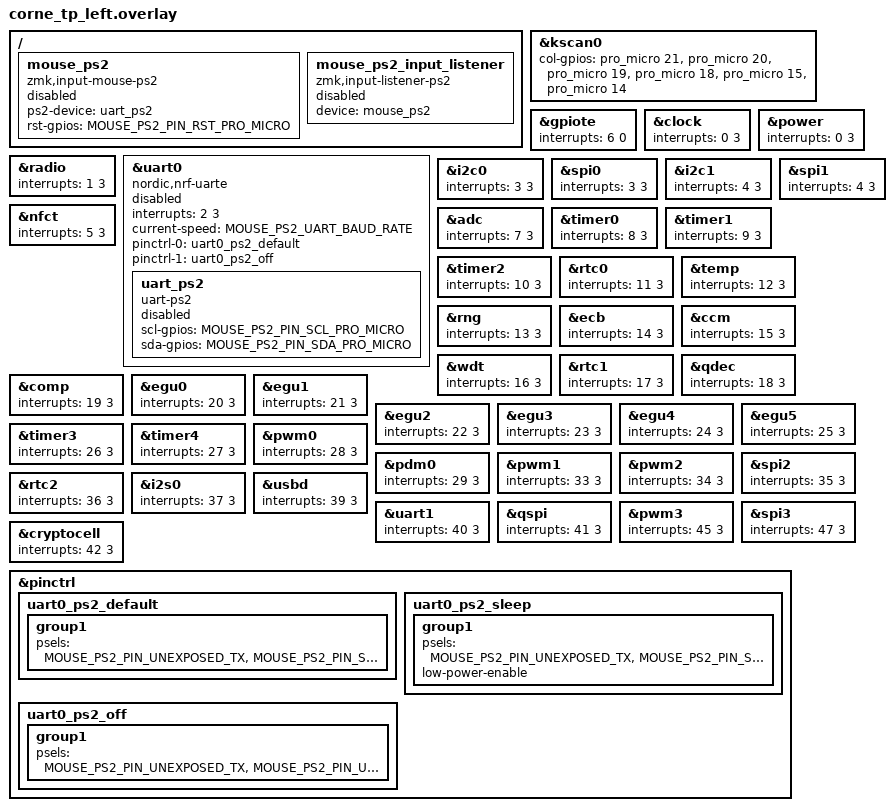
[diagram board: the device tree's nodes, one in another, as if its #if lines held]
/*
 * Copyright (c) 2020 Pete Johanson
 *
 * SPDX-License-Identifier: MIT
 */

#include "corne_tp.dtsi"

&kscan0 {
    col-gpios
        = <&pro_micro 21 GPIO_ACTIVE_HIGH>
        , <&pro_micro 20 GPIO_ACTIVE_HIGH>
        , <&pro_micro 19 GPIO_ACTIVE_HIGH>
        , <&pro_micro 18 GPIO_ACTIVE_HIGH>
        , <&pro_micro 15 GPIO_ACTIVE_HIGH>
        , <&pro_micro 14 GPIO_ACTIVE_HIGH>
        ;
};

#ifdef TRACKPOINT_ON_LEFT

#define MOUSE_PS2_DRIVER_UART

// The ideal pins are...
//   - D1 and D0 for clock and data, because they are high frequency.
//   - D8, D9, D16 or D10 for the trackpoint reset pin, because it doesn't
//     need to be high frequency (only needed if you are not using a reset
//     circuit)
//
// But on the corne keyboard, these pins are used for the backlight. So, this
// example config uses the pins D16 and D10 for clock and data and
// D9 for the reset circuit.
#define MOUSE_PS2_PIN_SCL_PRO_MICRO <&pro_micro 16 GPIO_ACTIVE_HIGH>
#define MOUSE_PS2_PIN_SDA_PRO_MICRO <&pro_micro 10 GPIO_ACTIVE_HIGH>

#define MOUSE_PS2_PIN_RST_PRO_MICRO <&pro_micro 9 GPIO_ACTIVE_HIGH>

// Configure SDA pin using the pinctrl notation
//
// Now configure SDA pin using the pinctrl notation. Make sure to use the same
// pin as in the pro micro notation, but convert it to the pinctrl notation.
//
// For the nice!nano you can find it on their pinout schematic, next to the
// pins, in the blue or violet boxes, with a format like `PX.YY` (P0.09).
//
// Enter it like `X, Y` without leading zeroes.
//
// Examples:
//      D1  - P0.06: 0, 6
// 		D0  - P0.08: 0, 8
//		D15 - P1.13: 1, 13
//		D16 - P0.10: 0, 10
//		D10 - P0.09: 0, 9
//
// We don't define the SCL pin, because UART uses a baud rate instead of
// a clock pin.
#define MOUSE_PS2_PIN_SDA_PINCTRL <NRF_PSEL(UART_RX, 0, 9)>

#define MOUSE_PS2_UART_BAUD_RATE <14400>

/*
 * PS/2 Mouse / Trackpoint - User Configuration if NOT using nice!nano
 *
 * WARNING: Do NOT change this if you are using a nice!nano v2 or clone.
 */

// Unexposed UART pins
// In UART two different pins are used for receiving and transmitting, but PS/2
// uses the same pin for both.
//
// The UART config still requires both pins to be configured. So we use one of
// the nrf52 pins that are not exposed on the nice!nano board.
//
// Do NOT change these if you are using a nice!nano (or a clone of it)
#define MOUSE_PS2_PIN_UNEXPOSED_TX <NRF_PSEL(UART_TX, 0, 27)>
#define MOUSE_PS2_PIN_UNEXPOSED_RX <NRF_PSEL(UART_RX, 0, 28)>


// Adjust GPIO interrupt priority to the highest level.
//
// IMPORTANT TLDR:
// If you are using the nice_nano_v2 board, you don't need to make changes to
// the config below and can leave it as it is.
//
// Explanation of these settings:
//
// PS/2 events must be processed within 30-50us, but frequently bluetooth and
// other interrupts take longer to finish.
//
// Therefore we change the default GPIO priority to the highest level (0) and
// demote all BT interrupt priorities by one level using the kconfig settings:
// - CONFIG_BT_CTLR_LLL_PRIO 1
// - CONFIG_BT_CTLR_ULL_HIGH_PRIO 2
// - CONFIG_BT_CTLR_ULL_LOW_PRIOCONFIG 2
//
// These config options are enabled automatically by the PS2 UART and GPIO
// drivers... so you don't have to enable them manually.
//
// Then we lower the interrupt priority of all other devices by 2 levels using
// the devicetree config below.
//
// This allows the PS/2 interrupts to be triggered faster and reduces
// transmission errors.
//
// If you are using the nice_nano_v2 board, you can reuse my config below.
//
// Otherwise, you can generate the interrupt overrides using this script:
// https://github.com/infused-kim/kb_zmk_ps2_mouse_trackpoint_driver/blob/main/scripts/gen_interrupt_priority_overrides.py
//
// Make sure to do it on a zephyr.dts where the interrupts have not been
// adjusted yet (i.e. a config that doesn't have the the following options
// enabled).
//
// If you are building using a toolchain you can find the zephyr.dts in the
// build directory, which by default is: `app/build/zephyr/zephyr.dts`
//
// If you are building using the github actions, copy the output of the build
// step `xxxx_right - nice_nano_v2 Devicetree file` into a file and run the
// script on it.

// gpiote should have the highest interrupt priority (0)
&gpiote {
    interrupts = < 6 0 >;
};

// All other priorities should be two levels lower than their defaults
// (which is usually 1 and should be demoted to 3)
&clock {
    interrupts = < 0 3 >;
};

&power {
    interrupts = < 0 3 >;
};

&radio {
    interrupts = < 1 3 >;
};

&uart0 {
    interrupts = < 2 3 >;
};

&i2c0 {
    interrupts = < 3 3 >;
};

&spi0 {
    interrupts = < 3 3 >;
};

&i2c1 {
    interrupts = < 4 3 >;
};

&spi1 {
    interrupts = < 4 3 >;
};

&nfct {
    interrupts = < 5 3 >;
};

&adc {
    interrupts = < 7 3 >;
};

&timer0 {
    interrupts = < 8 3 >;
};

&timer1 {
    interrupts = < 9 3 >;
};

&timer2 {
    interrupts = < 10 3 >;
};

&rtc0 {
    interrupts = < 11 3 >;
};

&temp {
    interrupts = < 12 3 >;
};

&rng {
    interrupts = < 13 3 >;
};

&ecb {
    interrupts = < 14 3 >;
};

&ccm {
    interrupts = < 15 3 >;
};

&wdt {
    interrupts = < 16 3 >;
};

&rtc1 {
    interrupts = < 17 3 >;
};

&qdec {
    interrupts = < 18 3 >;
};

&comp {
    interrupts = < 19 3 >;
};

&egu0 {
    interrupts = < 20 3 >;
};

&egu1 {
    interrupts = < 21 3 >;
};

&egu2 {
    interrupts = < 22 3 >;
};

&egu3 {
    interrupts = < 23 3 >;
};

&egu4 {
    interrupts = < 24 3 >;
};

&egu5 {
    interrupts = < 25 3 >;
};

&timer3 {
    interrupts = < 26 3 >;
};

&timer4 {
    interrupts = < 27 3 >;
};

&pwm0 {
    interrupts = < 28 3 >;
};

&pdm0 {
    interrupts = < 29 3 >;
};

&pwm1 {
    interrupts = < 33 3 >;
};

&pwm2 {
    interrupts = < 34 3 >;
};

&spi2 {
    interrupts = < 35 3 >;
};

&rtc2 {
    interrupts = < 36 3 >;
};

&i2s0 {
    interrupts = < 37 3 >;
};

&usbd {
    interrupts = < 39 3 >;
};

&uart1 {
    interrupts = < 40 3 >;
};

&qspi {
    interrupts = < 41 3 >;
};

&pwm3 {
    interrupts = < 45 3 >;
};

&spi3 {
    interrupts = < 47 3 >;
};

&cryptocell {
    interrupts = < 42 3 >;
};


/*
 * PS/2 Mouse / Trackpoint - Device Definitions
 *
 * WARNING: Do not change anything beyond here unless you know what you are
 *          doing.
 */


// Firmware with alternative pins
//
// This can safely be removed. It's only used in the example zmk-config repo
// to create an additional firmware with alternative PIN assignments.
//
// You can leave it or remove in your own zmk config. If you remove it, you
// should also remove the entry in `zmk-config-example/build.yaml` that uses
// it.
#ifdef MOUSE_PS2_ALT_PINS
    #undef MOUSE_PS2_PIN_SCL_PRO_MICRO
    #undef MOUSE_PS2_PIN_SDA_PRO_MICRO
    #undef MOUSE_PS2_PIN_SDA_PINCTRL

    #define MOUSE_PS2_PIN_SCL_PRO_MICRO <&pro_micro 1 GPIO_ACTIVE_HIGH>
    #define MOUSE_PS2_PIN_SDA_PRO_MICRO <&pro_micro 0 GPIO_ACTIVE_HIGH>
    #define MOUSE_PS2_PIN_SDA_PINCTRL <NRF_PSEL(UART_RX, 0, 8)>
#endif

// This define can be used in the keymap file to check whether the device tree
// configs in this file are present to void build errors on the side that does
// not have the mouse or TP
#define MOUSE_PS2_DT_PRESENT

&pinctrl {
	// This pinctrl state is used for receiving
	// For `UART_TX`, set an unused and unexposed pin
	// For `UART_RX`, set the PS/2 SDA pin number
	uart0_ps2_default: uart0_ps2_default {
		group1 {
			psels = MOUSE_PS2_PIN_UNEXPOSED_TX,
					MOUSE_PS2_PIN_SDA_PINCTRL;
		};
	};

	// Set this to the same pins as uart0_ps2_default
	uart0_ps2_sleep: uart0_ps2_sleep {
		group1 {
			psels = MOUSE_PS2_PIN_UNEXPOSED_TX,
					MOUSE_PS2_PIN_SDA_PINCTRL;
			low-power-enable;
		};
	};

	// The nrf52 UART controller is not compatible with the PS/2
	// transmission frame. So the PS/2 UART driver doesn't use UART for
	// transmissions and instead use GPIO bit-banging.
	//
	// When the driver switches to transmit mode, it frees up the SDA pin by
    // switching the UART controller to unexposed/unused pins.
	//
	// Then it configures the GPIO controller to use the SCL and SDA pins
	uart0_ps2_off: uart0_ps2_off {
		group1 {
			psels = MOUSE_PS2_PIN_UNEXPOSED_TX,
					MOUSE_PS2_PIN_UNEXPOSED_RX;
		};
	};
};


#ifdef MOUSE_PS2_DRIVER_UART

    &uart0 {
        status = "disabled";
        compatible = "nordic,nrf-uarte";

        current-speed = MOUSE_PS2_UART_BAUD_RATE;
        pinctrl-0 = <&uart0_ps2_default>;
        pinctrl-1 = <&uart0_ps2_off>;

        pinctrl-names = "default", "off";

        uart_ps2: uart_ps2 {
            status="disabled";
            compatible = "uart-ps2";
            scl-gpios = MOUSE_PS2_PIN_SCL_PRO_MICRO;
            sda-gpios = MOUSE_PS2_PIN_SDA_PRO_MICRO;
        };
    };

#else

    / {
        gpio_ps2: gpio_ps2 {
            status = "disabled";

            compatible = "gpio-ps2";
            scl-gpios = MOUSE_PS2_PIN_SCL_PRO_MICRO;
            sda-gpios = MOUSE_PS2_PIN_SDA_PRO_MICRO;
        };
    };

#endif


/ {
    mouse_ps2: mouse_ps2 {
		status = "disabled";
        compatible = "zmk,input-mouse-ps2";

#ifdef MOUSE_PS2_DRIVER_UART
	    ps2-device = <&uart_ps2>;
#else
	    ps2-device = <&gpio_ps2>;
#endif

#ifdef MOUSE_PS2_PIN_RST_PRO_MICRO
        rst-gpios = MOUSE_PS2_PIN_RST_PRO_MICRO;
#endif
    };

    mouse_ps2_input_listener: mouse_ps2_input_listener {
        compatible = "zmk,input-listener-ps2";
        status = "disabled";

        device = <&mouse_ps2>;

		// Some of the available settings depend on the keymap. So they
		// are adjusted in...
		// zmk-config/config/includes/mouse_tp.dtsi
    };
};

#endif // TRACKPOINT_ON_LEFT
